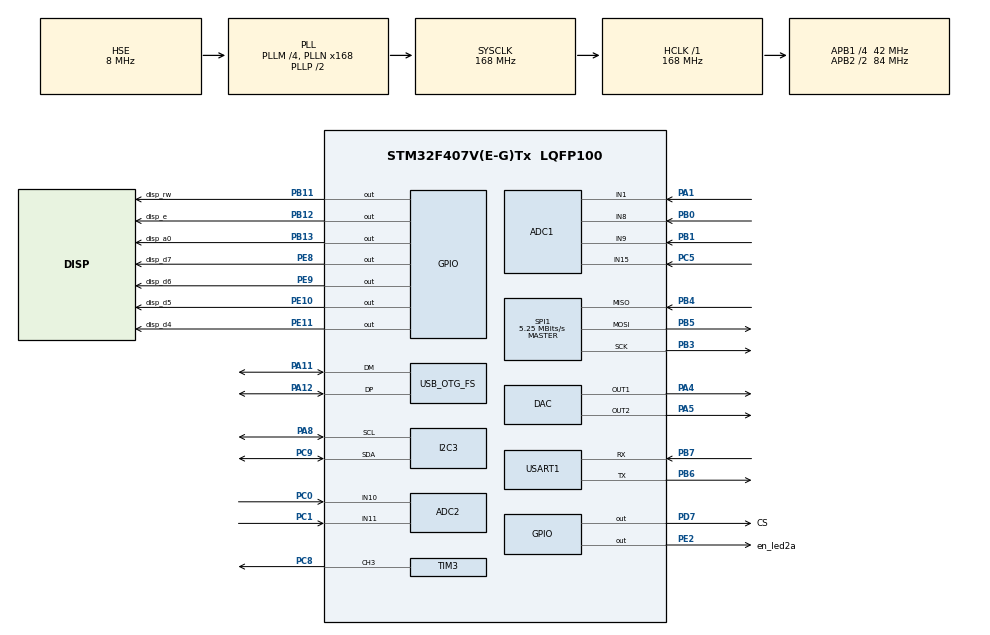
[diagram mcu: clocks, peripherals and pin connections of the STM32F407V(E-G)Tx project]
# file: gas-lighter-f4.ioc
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ADC1.Channel-0\#ChannelRegularConversion=ADC_CHANNEL_1
ADC1.Channel-1\#ChannelRegularConversion=ADC_CHANNEL_8
ADC1.Channel-2\#ChannelRegularConversion=ADC_CHANNEL_9
ADC1.Channel-3\#ChannelRegularConversion=ADC_CHANNEL_15
ADC1.ClockPrescaler=ADC_CLOCK_SYNC_PCLK_DIV8
ADC1.ContinuousConvMode=ENABLE
ADC1.DMAContinuousRequests=ENABLE
ADC1.ExternalTrigConv=ADC_SOFTWARE_START
ADC1.NbrOfConversion=4
ADC1.NbrOfConversionFlag=1
ADC1.Rank-0\#ChannelRegularConversion=1
ADC1.Rank-1\#ChannelRegularConversion=2
ADC1.Rank-2\#ChannelRegularConversion=3
ADC1.Rank-3\#ChannelRegularConversion=4
ADC1.SamplingTime-0\#ChannelRegularConversion=ADC_SAMPLETIME_480CYCLES
ADC1.SamplingTime-1\#ChannelRegularConversion=ADC_SAMPLETIME_480CYCLES
ADC1.SamplingTime-2\#ChannelRegularConversion=ADC_SAMPLETIME_480CYCLES
ADC1.SamplingTime-3\#ChannelRegularConversion=ADC_SAMPLETIME_480CYCLES
ADC1.ScanConvMode=ENABLE
ADC1.master=1
ADC2.Channel-0\#ChannelRegularConversion=ADC_CHANNEL_10
ADC2.Channel-1\#ChannelRegularConversion=ADC_CHANNEL_11
ADC2.ClockPrescaler=ADC_CLOCK_SYNC_PCLK_DIV8
ADC2.DMAContinuousRequests=ENABLE
ADC2.ExternalTrigConv=ADC_EXTERNALTRIGCONV_T8_TRGO
ADC2.NbrOfConversion=2
ADC2.NbrOfConversionFlag=1
ADC2.Rank-0\#ChannelRegularConversion=1
ADC2.Rank-1\#ChannelRegularConversion=2
ADC2.SamplingTime-0\#ChannelRegularConversion=ADC_SAMPLETIME_3CYCLES
ADC2.SamplingTime-1\#ChannelRegularConversion=ADC_SAMPLETIME_3CYCLES
ADC2.ScanConvMode=ENABLE
DAC.DAC_Trigger=DAC_TRIGGER_T8_TRGO
Dma.ADC1.3.Direction=DMA_PERIPH_TO_MEMORY
Dma.ADC1.3.FIFOMode=DMA_FIFOMODE_DISABLE
Dma.ADC1.3.Instance=DMA2_Stream0
Dma.ADC1.3.MemDataAlignment=DMA_MDATAALIGN_HALFWORD
Dma.ADC1.3.MemInc=DMA_MINC_ENABLE
Dma.ADC1.3.Mode=DMA_CIRCULAR
Dma.ADC1.3.PeriphDataAlignment=DMA_PDATAALIGN_HALFWORD
Dma.ADC1.3.PeriphInc=DMA_PINC_DISABLE
Dma.ADC1.3.Priority=DMA_PRIORITY_LOW
Dma.ADC2.1.Direction=DMA_PERIPH_TO_MEMORY
Dma.ADC2.1.FIFOMode=DMA_FIFOMODE_DISABLE
Dma.ADC2.1.Instance=DMA2_Stream2
Dma.ADC2.1.MemDataAlignment=DMA_MDATAALIGN_HALFWORD
Dma.ADC2.1.MemInc=DMA_MINC_ENABLE
Dma.ADC2.1.Mode=DMA_CIRCULAR
Dma.ADC2.1.PeriphDataAlignment=DMA_PDATAALIGN_HALFWORD
Dma.ADC2.1.PeriphInc=DMA_PINC_DISABLE
Dma.ADC2.1.Priority=DMA_PRIORITY_LOW
Dma.DAC1.2.Direction=DMA_MEMORY_TO_PERIPH
Dma.DAC1.2.FIFOMode=DMA_FIFOMODE_DISABLE
Dma.DAC1.2.Instance=DMA1_Stream5
Dma.DAC1.2.MemDataAlignment=DMA_MDATAALIGN_HALFWORD
Dma.DAC1.2.MemInc=DMA_MINC_ENABLE
Dma.DAC1.2.Mode=DMA_CIRCULAR
Dma.DAC1.2.PeriphDataAlignment=DMA_PDATAALIGN_HALFWORD
Dma.DAC1.2.PeriphInc=DMA_PINC_DISABLE
Dma.DAC1.2.Priority=DMA_PRIORITY_LOW
Dma.Request0=TIM8_CH4/TRIG/COM
Dma.Request1=ADC2
Dma.Request2=DAC1
Dma.Request3=ADC1
Dma.Request4=TIM3_CH3
Dma.TIM3_CH3.4.Direction=DMA_MEMORY_TO_PERIPH
Dma.TIM3_CH3.4.FIFOMode=DMA_FIFOMODE_DISABLE
Dma.TIM3_CH3.4.Instance=DMA1_Stream7
Dma.TIM3_CH3.4.MemDataAlignment=DMA_MDATAALIGN_HALFWORD
Dma.TIM3_CH3.4.MemInc=DMA_MINC_ENABLE
Dma.TIM3_CH3.4.Mode=DMA_CIRCULAR
Dma.TIM3_CH3.4.PeriphDataAlignment=DMA_PDATAALIGN_HALFWORD
Dma.TIM3_CH3.4.PeriphInc=DMA_PINC_DISABLE
Dma.TIM3_CH3.4.Priority=DMA_PRIORITY_LOW
Dma.TIM8_CH4/TRIG/COM.0.Direction=DMA_PERIPH_TO_MEMORY
Dma.TIM8_CH4/TRIG/COM.0.FIFOMode=DMA_FIFOMODE_DISABLE
Dma.TIM8_CH4/TRIG/COM.0.Instance=DMA2_Stream7
Dma.TIM8_CH4/TRIG/COM.0.MemDataAlignment=DMA_MDATAALIGN_HALFWORD
Dma.TIM8_CH4/TRIG/COM.0.MemInc=DMA_MINC_ENABLE
Dma.TIM8_CH4/TRIG/COM.0.Mode=DMA_NORMAL
Dma.TIM8_CH4/TRIG/COM.0.PeriphDataAlignment=DMA_PDATAALIGN_HALFWORD
Dma.TIM8_CH4/TRIG/COM.0.PeriphInc=DMA_PINC_DISABLE
Dma.TIM8_CH4/TRIG/COM.0.Priority=DMA_PRIORITY_LOW
Mcu.Family=STM32F4
Mcu.Name=STM32F407V(E-G)Tx
Mcu.Package=LQFP100
NVIC.DMA1_Stream5_IRQn=true\:5\:0\:true\:false\:true\:false\:true\:true
NVIC.DMA1_Stream7_IRQn=true\:0\:0\:false\:false\:true\:false\:true\:true
NVIC.DMA2_Stream0_IRQn=true\:5\:0\:true\:false\:true\:false\:true\:true
NVIC.DMA2_Stream2_IRQn=true\:5\:0\:true\:false\:true\:false\:true\:true
NVIC.DMA2_Stream7_IRQn=true\:5\:0\:true\:false\:true\:false\:true\:true
NVIC.OTG_FS_IRQn=true\:5\:0\:true\:false\:true\:true\:true\:true
NVIC.PriorityGroup=NVIC_PRIORITYGROUP_4
NVIC.TIM1_UP_TIM10_IRQn=true\:15\:0\:false\:false\:true\:false\:true\:true
NVIC.TIM8_UP_TIM13_IRQn=true\:5\:0\:true\:false\:true\:true\:true\:true
NVIC.TimeBase=TIM1_UP_TIM10_IRQn
NVIC.TimeBaseIP=TIM1
PA1.Signal=ADCx_IN1
PA11.Mode=Device_Only
PA11.Signal=USB_OTG_FS_DM
PA12.Mode=Device_Only
PA12.Signal=USB_OTG_FS_DP
PA13.Mode=Serial_Wire
PA13.Signal=SYS_JTMS-SWDIO
PA14.Mode=Serial_Wire
PA14.Signal=SYS_JTCK-SWCLK
PA4.Signal=COMP_DAC1_group
PA5.Signal=COMP_DAC2_group
PA8.Mode=I2C
PA8.Signal=I2C3_SCL
PB0.Signal=ADCx_IN8
PB1.Signal=ADCx_IN9
PB11.GPIO_Label=disp_rw
PB11.GPIO_Speed=GPIO_SPEED_FREQ_LOW
PB11.Signal=GPIO_Output
PB12.GPIO_Label=disp_e
PB12.GPIO_Speed=GPIO_SPEED_FREQ_LOW
PB12.Signal=GPIO_Output
PB13.GPIO_Label=disp_a0
PB13.GPIO_Speed=GPIO_SPEED_FREQ_LOW
PB13.Signal=GPIO_Output
PB3.Mode=Full_Duplex_Master
PB3.Signal=SPI1_SCK
PB4.Mode=Full_Duplex_Master
PB4.Signal=SPI1_MISO
PB5.Mode=Full_Duplex_Master
PB5.Signal=SPI1_MOSI
PB6.Mode=Asynchronous
PB6.Signal=USART1_TX
PB7.Mode=Asynchronous
PB7.Signal=USART1_RX
PC0.Signal=ADCx_IN10
PC1.Signal=ADCx_IN11
PC5.Signal=ADCx_IN15
PC8.Signal=S_TIM3_CH3
PC9.Mode=I2C
PC9.Signal=I2C3_SDA
PD7.GPIO_Label=CS
PD7.GPIO_Speed=GPIO_SPEED_FREQ_VERY_HIGH
PD7.PinState=GPIO_PIN_SET
PD7.Signal=GPIO_Output
PE10.GPIO_Label=disp_d5
PE10.GPIO_Speed=GPIO_SPEED_FREQ_LOW
PE10.Signal=GPIO_Output
PE11.GPIO_Label=disp_d4
PE11.GPIO_Speed=GPIO_SPEED_FREQ_LOW
PE11.Signal=GPIO_Output
PE2.GPIO_Label=en_led2a
PE2.GPIO_PuPd=GPIO_PULLDOWN
PE2.GPIO_Speed=GPIO_SPEED_FREQ_VERY_HIGH
PE2.Signal=GPIO_Output
PE8.GPIO_Label=disp_d7
PE8.GPIO_Speed=GPIO_SPEED_FREQ_LOW
PE8.Signal=GPIO_Output
PE9.GPIO_Label=disp_d6
PE9.GPIO_Speed=GPIO_SPEED_FREQ_LOW
PE9.Signal=GPIO_Output
PH0-OSC_IN.Mode=HSE-External-Oscillator
PH0-OSC_IN.Signal=RCC_OSC_IN
PH1-OSC_OUT.Mode=HSE-External-Oscillator
PH1-OSC_OUT.Signal=RCC_OSC_OUT
ProjectManager.HeapSize=0x200
ProjectManager.StackSize=0x400
ProjectManager.TargetToolchain=CMake
RCC.48MHZClocksFreq_Value=48000000
RCC.AHBFreq_Value=168000000
RCC.APB1CLKDivider=RCC_HCLK_DIV4
RCC.APB1Freq_Value=42000000
RCC.APB1TimFreq_Value=84000000
RCC.APB2CLKDivider=RCC_HCLK_DIV2
RCC.APB2Freq_Value=84000000
RCC.APB2TimFreq_Value=168000000
RCC.CortexFreq_Value=168000000
RCC.HCLKFreq_Value=168000000
RCC.HSE_VALUE=8000000
RCC.HSI_VALUE=16000000
RCC.LSE_VALUE=32768
RCC.PLLM=4
RCC.PLLN=168
RCC.PLLQ=7
RCC.SYSCLKFreq_VALUE=168000000
RCC.SYSCLKSource=RCC_SYSCLKSOURCE_PLLCLK
RCC.VCOOutputFreq_Value=336000000
SH.ADCx_IN1.0=ADC1_IN1,IN1
SH.ADCx_IN10.0=ADC2_IN10,IN10
SH.ADCx_IN11.0=ADC2_IN11,IN11
SH.ADCx_IN15.0=ADC1_IN15,IN15
SH.ADCx_IN8.0=ADC1_IN8,IN8
SH.ADCx_IN9.0=ADC1_IN9,IN9
SH.COMP_DAC1_group.0=DAC_OUT1,DAC_OUT1
SH.COMP_DAC2_group.0=DAC_OUT2,DAC_OUT2
SH.S_TIM3_CH3.0=TIM3_CH3,PWM Generation3 CH3
SPI1.BaudRatePrescaler=SPI_BAUDRATEPRESCALER_16
SPI1.CalculateBaudRate=5.25 MBits/s
SPI1.Direction=SPI_DIRECTION_2LINES
SPI1.Mode=SPI_MODE_MASTER
SPI1.VirtualType=VM_MASTER
TIM3.Channel-PWM\ Generation3\ CH3=TIM_CHANNEL_3
TIM3.Period=1000-1
TIM3.Prescaler=1000-1
TIM8.Prescaler=1
TIM8.TIM_MasterOutputTrigger=TIM_TRGO_UPDATE
USART1.VirtualMode=VM_ASYNC
USB_OTG_FS.VirtualMode=Device_Only
VP_SYS_VS_tim1.Mode=TIM1
VP_TIM3_VS_ClockSourceINT.Mode=Internal
VP_TIM8_VS_ClockSourceINT.Mode=Internal
board=custom

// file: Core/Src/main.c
/* USER CODE BEGIN Header */
/**
  ******************************************************************************
  * @file           : main.c
  * @brief          : Main program body
  ******************************************************************************
  * @attention
  *
  * Copyright (c) 2026 STMicroelectronics.
  * All rights reserved.
  *
  * This software is licensed under terms that can be found in the LICENSE file
  * in the root directory of this software component.
  * If no LICENSE file comes with this software, it is provided AS-IS.
  *
  ******************************************************************************
  */
/* USER CODE END Header */
#include "main.h"
#include "adc.h"
#include "dac.h"
#include "dma.h"
#include "i2c.h"
#include "spi.h"
#include "tim.h"
#include "usart.h"
#include "usb_otg.h"
#include "gpio.h"

/* USER CODE BEGIN Includes */
#include "app.h"
/* USER CODE END Includes */

void SystemClock_Config(void);

int main(void)
{

  /* USER CODE BEGIN 1 */
//#ifndef FOR_QEMU
//  SCB->VTOR = 0x08020000;
  SCB->VTOR = 0x08040200;
  __enable_irq();
//#endif
  /* USER CODE END 1 */

  /* MCU Configuration--------------------------------------------------------*/

  /* Reset of all peripherals, Initializes the Flash interface and the Systick. */
  HAL_Init();

  /* USER CODE BEGIN Init */
  init();
  /* USER CODE END Init */

  /* Configure the system clock */
  SystemClock_Config();

  /* Initialize all configured peripherals */
  MX_GPIO_Init();
  MX_DMA_Init();
  MX_USB_OTG_FS_PCD_Init();
  MX_USART1_UART_Init();
  MX_SPI1_Init();
  MX_ADC2_Init();
  MX_TIM8_Init();
  MX_DAC_Init();
  MX_ADC1_Init();
  MX_TIM3_Init();
  MX_I2C3_Init();
  /* USER CODE BEGIN 2 */
  setup();
  /* USER CODE END 2 */

  /* Infinite loop */
  while (1)
  {

  }
}

void SystemClock_Config(void)
{
  RCC_OscInitTypeDef RCC_OscInitStruct = {0};
  RCC_ClkInitTypeDef RCC_ClkInitStruct = {0};

  /** Configure the main internal regulator output voltage
  */
  __HAL_RCC_PWR_CLK_ENABLE();
  __HAL_PWR_VOLTAGESCALING_CONFIG(PWR_REGULATOR_VOLTAGE_SCALE1);

  /** Initializes the RCC Oscillators according to the specified parameters
  * in the RCC_OscInitTypeDef structure.
  */
  RCC_OscInitStruct.OscillatorType = RCC_OSCILLATORTYPE_HSE;
  RCC_OscInitStruct.HSEState = RCC_HSE_ON;
  RCC_OscInitStruct.PLL.PLLState = RCC_PLL_ON;
  RCC_OscInitStruct.PLL.PLLSource = RCC_PLLSOURCE_HSE;
  RCC_OscInitStruct.PLL.PLLM = 4;
  RCC_OscInitStruct.PLL.PLLN = 168;
  RCC_OscInitStruct.PLL.PLLP = RCC_PLLP_DIV2;
  RCC_OscInitStruct.PLL.PLLQ = 7;
  if (HAL_RCC_OscConfig(&RCC_OscInitStruct) != HAL_OK)
  {
    Error_Handler();
  }

  /** Initializes the CPU, AHB and APB buses clocks
  */
  RCC_ClkInitStruct.ClockType = RCC_CLOCKTYPE_HCLK|RCC_CLOCKTYPE_SYSCLK
                              |RCC_CLOCKTYPE_PCLK1|RCC_CLOCKTYPE_PCLK2;
  RCC_ClkInitStruct.SYSCLKSource = RCC_SYSCLKSOURCE_PLLCLK;
  RCC_ClkInitStruct.AHBCLKDivider = RCC_SYSCLK_DIV1;
  RCC_ClkInitStruct.APB1CLKDivider = RCC_HCLK_DIV4;
  RCC_ClkInitStruct.APB2CLKDivider = RCC_HCLK_DIV2;

  if (HAL_RCC_ClockConfig(&RCC_ClkInitStruct, FLASH_LATENCY_5) != HAL_OK)
  {
    Error_Handler();
  }
}

void HAL_TIM_PeriodElapsedCallback(TIM_HandleTypeDef *htim)
{
  if (htim->Instance == TIM1)
  {
    HAL_IncTick();
  }
}

void Error_Handler(void)
{
  __disable_irq();
  while (1)
  {
  }
}
